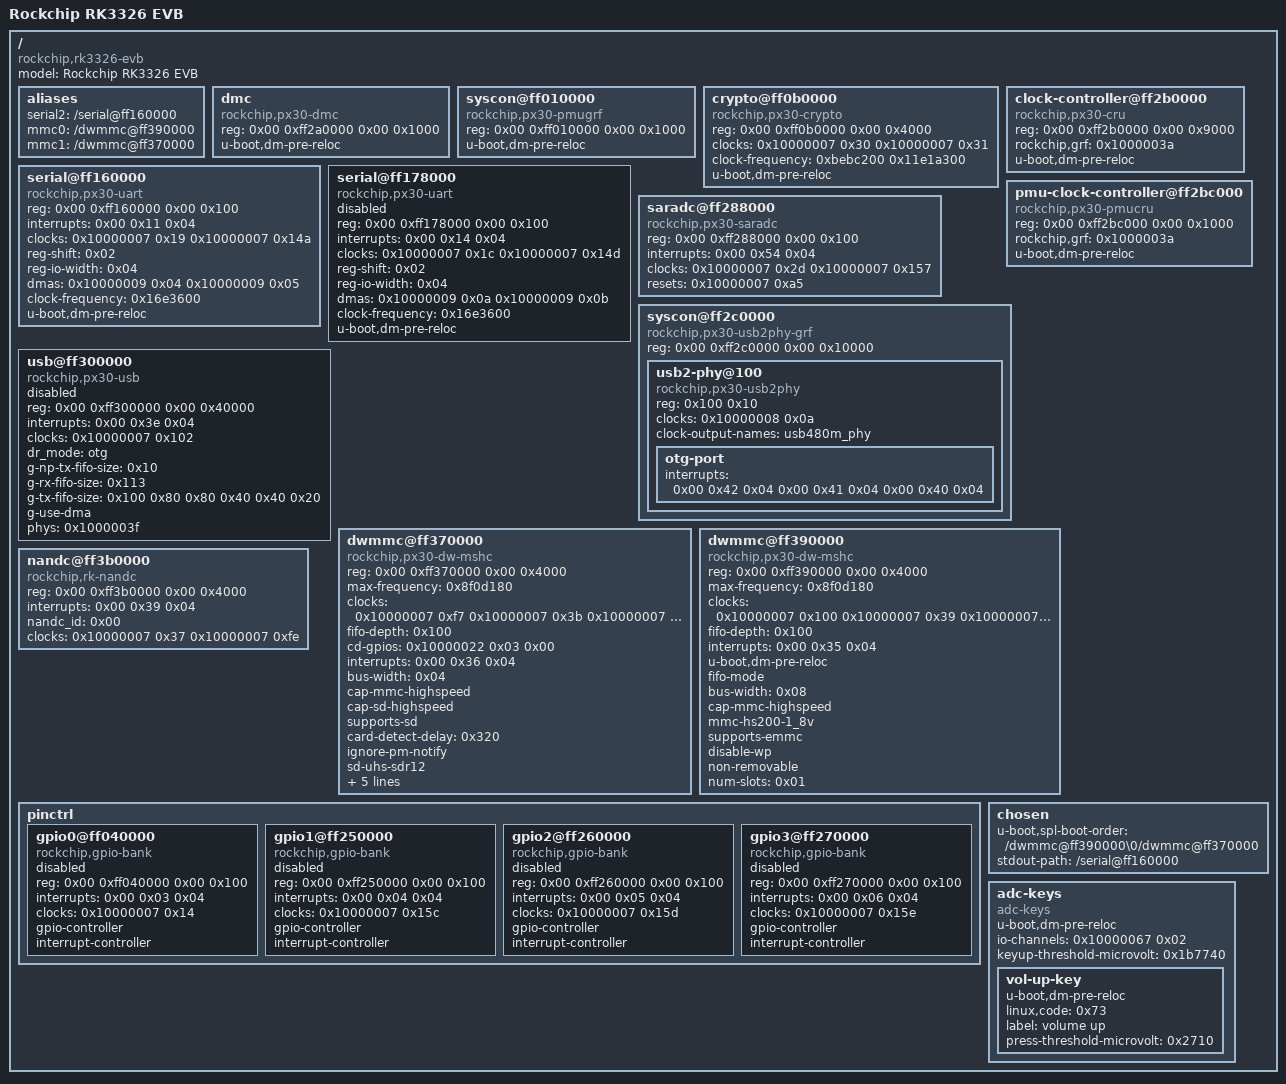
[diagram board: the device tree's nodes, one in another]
/dts-v1/;

/ {
	compatible = "rockchip,rk3326-evb\0rockchip,rk3326";
	#address-cells = <0x02>;
	#size-cells = <0x02>;
	model = "Rockchip RK3326 EVB";

	aliases {
		serial2 = "/serial@ff160000";
		mmc0 = "/dwmmc@ff390000";
		mmc1 = "/dwmmc@ff370000";
	};

	dmc {
		compatible = "rockchip,px30-dmc\0syscon";
		reg = <0x00 0xff2a0000 0x00 0x1000>;
		u-boot,dm-pre-reloc;
	};

	syscon@ff010000 {
		compatible = "rockchip,px30-pmugrf\0syscon\0simple-mfd";
		reg = <0x00 0xff010000 0x00 0x1000>;
		#address-cells = <0x01>;
		#size-cells = <0x01>;
		u-boot,dm-pre-reloc;
		phandle = <0x1000005d>;
	};

	crypto@ff0b0000 {
		compatible = "rockchip,px30-crypto";
		reg = <0x00 0xff0b0000 0x00 0x4000>;
		clock-names = "sclk_crypto\0apkclk_crypto";
		clocks = <0x10000007 0x30 0x10000007 0x31>;
		clock-frequency = <0xbebc200 0x11e1a300>;
		status = "okay";
		u-boot,dm-pre-reloc;
	};

	serial@ff160000 {
		compatible = "rockchip,px30-uart\0snps,dw-apb-uart";
		reg = <0x00 0xff160000 0x00 0x100>;
		interrupts = <0x00 0x11 0x04>;
		clocks = <0x10000007 0x19 0x10000007 0x14a>;
		clock-names = "baudclk\0apb_pclk";
		reg-shift = <0x02>;
		reg-io-width = <0x04>;
		dmas = <0x10000009 0x04 0x10000009 0x05>;
		#dma-cells = <0x02>;
		status = "okay";
		clock-frequency = <0x16e3600>;
		u-boot,dm-pre-reloc;
	};

	serial@ff178000 {
		compatible = "rockchip,px30-uart\0snps,dw-apb-uart";
		reg = <0x00 0xff178000 0x00 0x100>;
		interrupts = <0x00 0x14 0x04>;
		clocks = <0x10000007 0x1c 0x10000007 0x14d>;
		clock-names = "baudclk\0apb_pclk";
		reg-shift = <0x02>;
		reg-io-width = <0x04>;
		dmas = <0x10000009 0x0a 0x10000009 0x0b>;
		#dma-cells = <0x02>;
		status = "disabled";
		clock-frequency = <0x16e3600>;
		u-boot,dm-pre-reloc;
	};

	saradc@ff288000 {
		compatible = "rockchip,px30-saradc\0rockchip,rk3399-saradc";
		reg = <0x00 0xff288000 0x00 0x100>;
		interrupts = <0x00 0x54 0x04>;
		#io-channel-cells = <0x01>;
		clocks = <0x10000007 0x2d 0x10000007 0x157>;
		clock-names = "saradc\0apb_pclk";
		resets = <0x10000007 0xa5>;
		reset-names = "saradc-apb";
		status = "okay";
		u-boot,dm-spl;
		phandle = <0x10000067>;
	};

	clock-controller@ff2b0000 {
		compatible = "rockchip,px30-cru";
		reg = <0x00 0xff2b0000 0x00 0x9000>;
		rockchip,grf = <0x1000003a>;
		#clock-cells = <0x01>;
		#reset-cells = <0x01>;
		u-boot,dm-pre-reloc;
		phandle = <0x10000007>;
	};

	pmu-clock-controller@ff2bc000 {
		compatible = "rockchip,px30-pmucru";
		reg = <0x00 0xff2bc000 0x00 0x1000>;
		rockchip,grf = <0x1000003a>;
		#clock-cells = <0x01>;
		#reset-cells = <0x01>;
		u-boot,dm-pre-reloc;
		phandle = <0x10000008>;
	};

	syscon@ff2c0000 {
		compatible = "rockchip,px30-usb2phy-grf\0syscon\0simple-mfd";
		reg = <0x00 0xff2c0000 0x00 0x10000>;
		#address-cells = <0x01>;
		#size-cells = <0x01>;
		u-boot,dm-spl;
		status = "okay";

		usb2-phy@100 {
			compatible = "rockchip,px30-usb2phy\0rockchip,rk3328-usb2phy";
			reg = <0x100 0x10>;
			clocks = <0x10000008 0x0a>;
			clock-names = "phyclk";
			#clock-cells = <0x00>;
			clock-output-names = "usb480m_phy";
			status = "okay";
			u-boot,dm-spl;
			phandle = <0x1000003d>;

			otg-port {
				#phy-cells = <0x00>;
				interrupts = <0x00 0x42 0x04 0x00 0x41 0x04 0x00 0x40 0x04>;
				interrupt-names = "otg-bvalid\0otg-id\0linestate";
				status = "okay";
				u-boot,dm-spl;
				phandle = <0x1000003f>;
			};
		};
	};

	usb@ff300000 {
		compatible = "rockchip,px30-usb\0rockchip,rk3066-usb\0snps,dwc2";
		reg = <0x00 0xff300000 0x00 0x40000>;
		interrupts = <0x00 0x3e 0x04>;
		clocks = <0x10000007 0x102>;
		clock-names = "otg";
		dr_mode = "otg";
		g-np-tx-fifo-size = <0x10>;
		g-rx-fifo-size = <0x113>;
		g-tx-fifo-size = <0x100 0x80 0x80 0x40 0x40 0x20>;
		g-use-dma;
		phys = <0x1000003f>;
		phy-names = "usb2-phy";
		status = "disabled";
		u-boot,dm-spl;
	};

	dwmmc@ff370000 {
		compatible = "rockchip,px30-dw-mshc\0rockchip,rk3288-dw-mshc";
		reg = <0x00 0xff370000 0x00 0x4000>;
		max-frequency = <0x8f0d180>;
		clocks = <0x10000007 0xf7 0x10000007 0x3b 0x10000007 0x43 0x10000007 0x44>;
		clock-names = "biu\0ciu\0ciu-drv\0ciu-sample";
		fifo-depth = <0x100>;
		cd-gpios = <0x10000022 0x03 0x00>;
		interrupts = <0x00 0x36 0x04>;
		status = "okay";
		u-boot,dm-spl;
		bus-width = <0x04>;
		cap-mmc-highspeed;
		cap-sd-highspeed;
		supports-sd;
		card-detect-delay = <0x320>;
		ignore-pm-notify;
		sd-uhs-sdr12;
		sd-uhs-sdr25;
		sd-uhs-sdr50;
		sd-uhs-sdr104;
		vqmmc-supply = <0x10000047>;
		vmmc-supply = <0x10000048>;
	};

	dwmmc@ff390000 {
		compatible = "rockchip,px30-dw-mshc\0rockchip,rk3288-dw-mshc";
		reg = <0x00 0xff390000 0x00 0x4000>;
		max-frequency = <0x8f0d180>;
		clocks = <0x10000007 0x100 0x10000007 0x39 0x10000007 0x47 0x10000007 0x48>;
		clock-names = "biu\0ciu\0ciu-drv\0ciu-sample";
		fifo-depth = <0x100>;
		interrupts = <0x00 0x35 0x04>;
		status = "okay";
		u-boot,dm-spl;
		u-boot,dm-pre-reloc;
		fifo-mode;
		bus-width = <0x08>;
		cap-mmc-highspeed;
		mmc-hs200-1_8v;
		supports-emmc;
		disable-wp;
		non-removable;
		num-slots = <0x01>;
	};

	nandc@ff3b0000 {
		compatible = "rockchip,rk-nandc";
		reg = <0x00 0xff3b0000 0x00 0x4000>;
		interrupts = <0x00 0x39 0x04>;
		nandc_id = <0x00>;
		clocks = <0x10000007 0x37 0x10000007 0xfe>;
		clock-names = "clk_nandc\0hclk_nandc";
		status = "okay";
		u-boot,dm-spl;
	};

	pinctrl {

		gpio0@ff040000 {
			compatible = "rockchip,gpio-bank";
			reg = <0x00 0xff040000 0x00 0x100>;
			interrupts = <0x00 0x03 0x04>;
			clocks = <0x10000007 0x14>;
			gpio-controller;
			#gpio-cells = <0x02>;
			interrupt-controller;
			#interrupt-cells = <0x02>;
			u-boot,dm-spl;
			status = "disabled";
			phandle = <0x10000022>;
		};

		gpio1@ff250000 {
			compatible = "rockchip,gpio-bank";
			reg = <0x00 0xff250000 0x00 0x100>;
			interrupts = <0x00 0x04 0x04>;
			clocks = <0x10000007 0x15c>;
			gpio-controller;
			#gpio-cells = <0x02>;
			interrupt-controller;
			#interrupt-cells = <0x02>;
			u-boot,dm-spl;
			status = "disabled";
		};

		gpio2@ff260000 {
			compatible = "rockchip,gpio-bank";
			reg = <0x00 0xff260000 0x00 0x100>;
			interrupts = <0x00 0x05 0x04>;
			clocks = <0x10000007 0x15d>;
			gpio-controller;
			#gpio-cells = <0x02>;
			interrupt-controller;
			#interrupt-cells = <0x02>;
			u-boot,dm-spl;
			status = "disabled";
		};

		gpio3@ff270000 {
			compatible = "rockchip,gpio-bank";
			reg = <0x00 0xff270000 0x00 0x100>;
			interrupts = <0x00 0x06 0x04>;
			clocks = <0x10000007 0x15e>;
			gpio-controller;
			#gpio-cells = <0x02>;
			interrupt-controller;
			#interrupt-cells = <0x02>;
			u-boot,dm-spl;
			status = "disabled";
		};
	};

	chosen {
		u-boot,spl-boot-order = "/dwmmc@ff390000\0/dwmmc@ff370000";
		stdout-path = "/serial@ff160000";
	};

	adc-keys {
		u-boot,dm-pre-reloc;
		compatible = "adc-keys";
		io-channels = <0x10000067 0x02>;
		io-channel-names = "buttons";
		keyup-threshold-microvolt = <0x1b7740>;

		vol-up-key {
			u-boot,dm-pre-reloc;
			linux,code = <0x73>;
			label = "volume up";
			press-threshold-microvolt = <0x2710>;
		};
	};
};
